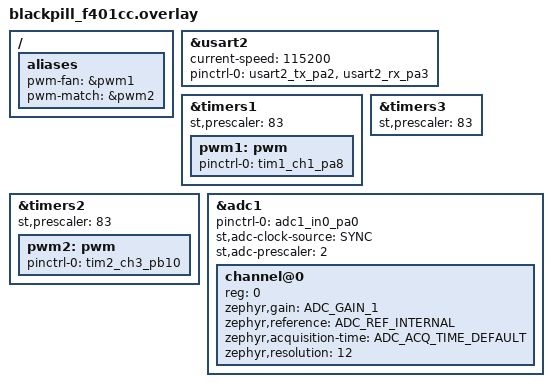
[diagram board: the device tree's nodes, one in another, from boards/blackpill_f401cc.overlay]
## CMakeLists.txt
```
cmake_minimum_required(VERSION 3.20.0)
find_package(Zephyr REQUIRED HINTS $ENV{ZEPHYR_BASE})
project(dut_stm32_3)

target_sources(app PRIVATE
    src/main.c
    src/switch_led.c
    src/fan_pwm.c
    src/uart_echo.c
    src/pwm_match.c
    src/spi_cmd.c
)

target_include_directories(app PRIVATE src)
```

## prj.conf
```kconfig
CONFIG_GPIO=y
CONFIG_ADC=y
CONFIG_PWM=y
CONFIG_UART_INTERRUPT_DRIVEN=y
CONFIG_SERIAL=y
CONFIG_PRINTK=y
CONFIG_UART_CONSOLE=y
CONFIG_ADC_STM32=y
CONFIG_SPI=y
CONFIG_SPI_SLAVE=y
```

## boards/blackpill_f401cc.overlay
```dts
#include <zephyr/dt-bindings/adc/adc.h>

/ {
    aliases {
        pwm-fan   = &pwm1;
        pwm-match = &pwm2;
    };
};

&usart2 {
    status = "okay";
    current-speed = <115200>;
    pinctrl-0 = <&usart2_tx_pa2 &usart2_rx_pa3>;
    pinctrl-names = "default";
};

&timers1 {
    status = "okay";
    st,prescaler = <83>;
    pwm1: pwm {
        status = "okay";
        pinctrl-0 = <&tim1_ch1_pa8>;
        pinctrl-names = "default";
    };
};

&timers2 {
    status = "okay";
    st,prescaler = <83>;
    pwm2: pwm {
        status = "okay";
        pinctrl-0 = <&tim2_ch3_pb10>;
        pinctrl-names = "default";
    };
};

&timers3 {
    status = "okay";
    st,prescaler = <83>;
};

&adc1 {
    status = "okay";
    pinctrl-0 = <&adc1_in0_pa0>;
    pinctrl-names = "default";
    st,adc-clock-source = "SYNC";
    st,adc-prescaler = <2>;
    #address-cells = <1>;
    #size-cells = <0>;

    channel@0 {
        reg = <0>;
        zephyr,gain = "ADC_GAIN_1";
        zephyr,reference = "ADC_REF_INTERNAL";
        zephyr,acquisition-time = <ADC_ACQ_TIME_DEFAULT>;
        zephyr,resolution = <12>;
    };
};
```

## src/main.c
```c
#include <zephyr/kernel.h>
#include <zephyr/device.h>
#include "switch_led.h"
#include "fan_pwm.h"
#include "uart_echo.h"
#include "pwm_match.h"
#include "spi_cmd.h"

K_SEM_DEFINE(pwm_match_ready, 0, 1);

K_THREAD_DEFINE(spi_cmd_tid, 1024, spi_cmd_thread, NULL, NULL, NULL, 4, 0, 0);
K_THREAD_DEFINE(pwm_match_tid, 2048,
                pwm_match_thread, NULL, NULL, NULL,
                5, 0, 0);

int main(void)
{
    printk("DUT3 starting\n");

    if (switch_led_init() != 0) {
        printk("switch_led init failed\n");
        return 0;
    }

    if (fan_pwm_init() != 0) {
        printk("fan_pwm init failed\n");
        return 0;
    }

    if (uart_echo_init() != 0) {
        printk("uart_echo init failed\n");
        return 0;
    }

    if (spi_cmd_init() != 0) {
        printk("spi_cmd init failed\n");
        return 0;
    }

    if (pwm_match_init() != 0) {
        printk("pwm_match init failed\n");
        return 0;
    }

    k_sem_give(&pwm_match_ready);

    printk("DUT3 ready\n");

    while (1) {
        switch_led_update();
        fan_pwm_update();
        k_msleep(10);
    }

    return 0;
}
```

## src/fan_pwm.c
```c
#include "fan_pwm.h"
#include <zephyr/drivers/adc.h>
#include <zephyr/drivers/pwm.h>

#define ADC_NODE DT_NODELABEL(adc1)
#define PWM_NODE DT_ALIAS(pwm_fan)
#define PWM_FREQ_HZ 1000u
#define PWM_PERIOD_NS (1000000000u / PWM_FREQ_HZ)
#define ADC_MAX 4095u

static const struct device *adc_dev;
static const struct device *pwm_dev;

static struct adc_channel_cfg ch_cfg = {
    .gain = ADC_GAIN_1,
    .reference = ADC_REF_INTERNAL,
    .acquisition_time = ADC_ACQ_TIME_DEFAULT,
    .channel_id = 0,
};

int fan_pwm_init(void)
{
    adc_dev = DEVICE_DT_GET(ADC_NODE);
    if (!device_is_ready(adc_dev))
        return -1;

    pwm_dev = DEVICE_DT_GET(PWM_NODE);
    if (!device_is_ready(pwm_dev))
        return -1;

    adc_channel_setup(adc_dev, &ch_cfg);
    return 0;
}

void fan_pwm_update(void)
{
    static int count = 0;

    int16_t buf;
    struct adc_sequence seq = {
        .channels = BIT(0),
        .buffer = &buf,
        .buffer_size = sizeof(buf),
        .resolution = 12,
    };

    if (adc_read(adc_dev, &seq) != 0)
        return;

    uint32_t duty_pct = (uint32_t)buf * 100u / ADC_MAX;
    uint32_t pulse_ns = PWM_PERIOD_NS * duty_pct / 100u;
    pwm_set(pwm_dev, 1, PWM_PERIOD_NS, pulse_ns, 0);

    if (++count >= 50)
    {
        count = 0;
        printk("ADC: %d duty: %d%%\n", buf, duty_pct);
    }
}
```

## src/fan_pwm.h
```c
#ifndef FAN_PWM_H
#define FAN_PWM_H
int  fan_pwm_init(void);
void fan_pwm_update(void);
#endif
```

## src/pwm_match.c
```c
#include "pwm_match.h"
#include <zephyr/kernel.h>
#include <zephyr/drivers/gpio.h>
#include <zephyr/drivers/pwm.h>

/*
 * Reads PWM signal on PB4 via GPIO interrupt (3-edge capture)
 * Reproduces same freq/duty on PB10 via TIM2 CH3
 */

#define CAPTURE_PIN     4
#define GPIOB_NODE      DT_NODELABEL(gpiob)
#define PWM_MATCH_NODE  DT_ALIAS(pwm_match)
#define EDGES_NEEDED    3

static const struct device *gpio_dev;
static const struct device *pwm_dev;
static struct gpio_callback  cap_cb;

static volatile uint32_t edge_times[EDGES_NEEDED];
static volatile int      edge_levels[EDGES_NEEDED];
static volatile int      edge_count;
static struct k_sem      cap_sem;
static volatile bool     cap_active;

static void capture_isr(const struct device *dev,
                        struct gpio_callback *cb,
                        uint32_t pins)
{
    ARG_UNUSED(cb);
    ARG_UNUSED(pins);

    if (!cap_active) return;

    int idx = edge_count;
    if (idx < EDGES_NEEDED) {
        edge_times[idx]  = k_cycle_get_32();
        edge_levels[idx] = gpio_pin_get_raw(dev, CAPTURE_PIN);
        edge_count = idx + 1;
    }

    if (edge_count == EDGES_NEEDED) {
        cap_active = false;
        k_sem_give(&cap_sem);
    }
}

int pwm_match_init(void)
{
    gpio_dev = DEVICE_DT_GET(GPIOB_NODE);
    if (!device_is_ready(gpio_dev)) return -1;

    pwm_dev = DEVICE_DT_GET(PWM_MATCH_NODE);
    if (!device_is_ready(pwm_dev)) return -1;

    gpio_pin_configure(gpio_dev, CAPTURE_PIN, GPIO_INPUT | GPIO_PULL_DOWN);
    k_sem_init(&cap_sem, 0, 1);
    cap_active  = false;
    edge_count  = 0;

    gpio_init_callback(&cap_cb, capture_isr, BIT(CAPTURE_PIN));
    gpio_add_callback(gpio_dev, &cap_cb);

    return 0;
}

void pwm_match_update(void)
{
    edge_count = 0;
    cap_active = false;
    k_sem_reset(&cap_sem);

    gpio_pin_interrupt_configure(gpio_dev, CAPTURE_PIN, GPIO_INT_EDGE_BOTH);
    cap_active = true;

    /* wait up to 500ms for 3 edges */
    int ret = k_sem_take(&cap_sem, K_MSEC(500));

    gpio_pin_interrupt_configure(gpio_dev, CAPTURE_PIN, GPIO_INT_DISABLE);
    cap_active = false;

    if (ret != 0) { printk("match: timeout\n"); return; }
    if (edge_count < EDGES_NEEDED) return;

    uint32_t cpu_hz    = sys_clock_hw_cycles_per_sec();
    uint32_t period_cy = edge_times[2] - edge_times[0];
    uint32_t pulse_cy;

    if (edge_levels[0] == 1) {
        pulse_cy = edge_times[1] - edge_times[0];
    } else {
        pulse_cy = edge_times[2] - edge_times[1];
    }

    if (period_cy == 0 || pulse_cy == 0 || pulse_cy >= period_cy) { printk("match: bad edge data\n"); return; }

    uint32_t freq_hz   = cpu_hz / period_cy;
    uint32_t duty_pct  = pulse_cy * 100u / period_cy;

    if (freq_hz == 0 || freq_hz > 10000) { printk("match: freq out of range %u\n", freq_hz); return; }

    uint32_t period_ns = 1000000000u / freq_hz;
    uint32_t pulse_ns  = period_ns * duty_pct / 100u;

    printk("match: freq=%u duty=%u\n", freq_hz, duty_pct);
    int r = pwm_set(pwm_dev, 3, period_ns, pulse_ns, 0);
    printk("pwm_set ret=%d\n", r);
}

extern struct k_sem pwm_match_ready;

void pwm_match_thread(void *a, void *b, void *c)
{
    ARG_UNUSED(a); ARG_UNUSED(b); ARG_UNUSED(c);
    k_sem_take(&pwm_match_ready, K_FOREVER);
    printk("pwm_match thread started\n");
    while (1) {
        pwm_match_update();
    }
}
```

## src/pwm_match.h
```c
#ifndef PWM_MATCH_H
#define PWM_MATCH_H
int  pwm_match_init(void);
void pwm_match_update(void);
void pwm_match_thread(void *a, void *b, void *c);
#endif
```

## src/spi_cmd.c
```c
#include "spi_cmd.h"
#include <zephyr/kernel.h>
#include <zephyr/drivers/spi.h>
#include <zephyr/drivers/gpio.h>
#include <string.h>

#define SPI_NODE    DT_NODELABEL(spi1)
#define LED_PIN     5
#define GPIOB_NODE  DT_NODELABEL(gpiob)

static const struct device *spi_dev;
static const struct device *gpiob_dev;

static const struct spi_config slave_cfg = {
    .frequency = 500000,
    .operation = SPI_OP_MODE_SLAVE |
                 SPI_TRANSFER_MSB  |
                 SPI_WORD_SET(8)   |
                 SPI_LINES_SINGLE,
    .slave = 0,
};

int spi_cmd_init(void)
{
    spi_dev = DEVICE_DT_GET(SPI_NODE);
    if (!device_is_ready(spi_dev)) {
        printk("SPI1 slave not ready\n");
        return -1;
    }

    gpiob_dev = DEVICE_DT_GET(GPIOB_NODE);
    if (!device_is_ready(gpiob_dev)) return -1;

    gpio_pin_configure(gpiob_dev, LED_PIN, GPIO_OUTPUT_INACTIVE);

    printk("SPI1 slave ready\n");
    return 0;
}

void spi_cmd_thread(void *a, void *b, void *c)
{
    ARG_UNUSED(a); ARG_UNUSED(b); ARG_UNUSED(c);

    uint8_t rx_buf[8];
    uint8_t tx_buf[8] = {0};

    while (1) {
        memset(rx_buf, 0, sizeof(rx_buf));

        struct spi_buf rx_bufs[] = {{ .buf = rx_buf, .len = 1 }};
        struct spi_buf tx_bufs[] = {{ .buf = tx_buf, .len = 1 }};

        struct spi_buf_set rx_set = { .buffers = rx_bufs, .count = 1 };
        struct spi_buf_set tx_set = { .buffers = tx_bufs, .count = 1 };

        int ret = spi_transceive(spi_dev, &slave_cfg, &tx_set, &rx_set);

        printk("SPI ret=%d rx=0x%02x\n", ret, rx_buf[0]);
        if (ret >= 0) {
            uint8_t cmd = rx_buf[0];
            printk("SPI RX: 0x%02x\n", cmd);

            if (cmd == 0x01) {
                gpio_pin_set_raw(gpiob_dev, LED_PIN, 1);
                printk("SPI CMD: LED_ON\n");
            } else if (cmd == 0x00) {
                gpio_pin_set_raw(gpiob_dev, LED_PIN, 0);
                printk("SPI CMD: LED_OFF\n");
            }
        } else {
            printk("SPI error: %d\n", ret);
        }
    }
}
```

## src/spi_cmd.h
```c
#ifndef SPI_CMD_H
#define SPI_CMD_H
int  spi_cmd_init(void);
void spi_cmd_thread(void *a, void *b, void *c);
#endif
```

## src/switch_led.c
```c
#include "switch_led.h"
#include <zephyr/drivers/gpio.h>

#define SWITCH_NODE  DT_NODELABEL(gpiob)
#define SWITCH_PIN   0
#define LED_PIN      1

static const struct device *gpio_dev;

int switch_led_init(void)
{
    gpio_dev = DEVICE_DT_GET(SWITCH_NODE);
    if (!device_is_ready(gpio_dev)) return -1;

    gpio_pin_configure(gpio_dev, SWITCH_PIN, GPIO_INPUT | GPIO_PULL_DOWN);
    gpio_pin_configure(gpio_dev, LED_PIN,    GPIO_OUTPUT_INACTIVE);

    return 0;
}

void switch_led_update(void)
{
    int val = gpio_pin_get_raw(gpio_dev, SWITCH_PIN);
    gpio_pin_set_raw(gpio_dev, LED_PIN, val);
}
```

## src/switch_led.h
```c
#ifndef SWITCH_LED_H
#define SWITCH_LED_H
int  switch_led_init(void);
void switch_led_update(void);
#endif
```

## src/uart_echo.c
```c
#include "uart_echo.h"
#include <zephyr/drivers/uart.h>
#include <zephyr/kernel.h>
#include <string.h>

#define UART_NODE   DT_NODELABEL(usart2)
#define BUF_SIZE    64

static const struct device *uart_dev;
static char rx_buf[BUF_SIZE];
static int  rx_idx;

static void uart_cb(const struct device *dev, void *user_data)
{
    ARG_UNUSED(user_data);

    if (!uart_irq_update(dev)) return;

    while (uart_irq_rx_ready(dev)) {
        uint8_t c;
        uart_fifo_read(dev, &c, 1);

        if (c == '\n' || c == '\r') {
            if (rx_idx > 0) {
                rx_buf[rx_idx] = '\0';
                /* echo back */
                for (int i = 0; i < rx_idx; i++) {
                    uart_poll_out(dev, rx_buf[i]);
                }
                uart_poll_out(dev, '\r');
                uart_poll_out(dev, '\n');
                rx_idx = 0;
            }
        } else if (rx_idx < BUF_SIZE - 1) {
            rx_buf[rx_idx++] = c;
        }
    }
}

int uart_echo_init(void)
{
    uart_dev = DEVICE_DT_GET(UART_NODE);
    if (!device_is_ready(uart_dev)) return -1;

    uart_irq_callback_set(uart_dev, uart_cb);
    uart_irq_rx_enable(uart_dev);

    return 0;
}
```

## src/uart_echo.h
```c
#ifndef UART_ECHO_H
#define UART_ECHO_H
int uart_echo_init(void);
#endif
```
